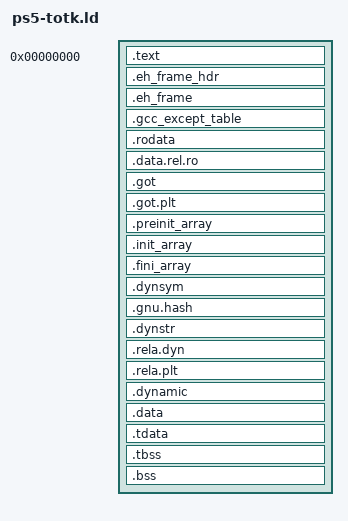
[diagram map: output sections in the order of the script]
/*
 * ps5/ps5-totk.ld
 *
 * PS5 PIE linker script for TOTK (PPSA99199).
 * Extends the PS5 kit's ps5-pie-unwind.ld by keeping TOTK's HOST_OVERRIDE
 * (`totk_ovr`) and HOST_OBSERVER (`totk_obs`) tables inside `: relro` with
 * explicit __start_totk_* / __stop_totk_* markers so --gc-sections never
 * strips them and PIE relocations fix up every entry's string & function ptr.
 */

OUTPUT_FORMAT("elf64-x86-64")
OUTPUT_ARCH(i386:x86-64)

PHDRS {
    text PT_LOAD FLAGS (0x5);
    ro PT_LOAD FLAGS (0x4);
    relro PT_LOAD FLAGS (0x6);
    data PT_LOAD FLAGS (0x6);
    dynamic PT_DYNAMIC FLAGS (0x6);
}

SECTIONS {
    .text 0 : ALIGN(CONSTANT(MAXPAGESIZE)) {
        QUAD(0xcccccccccccccccc)
        QUAD(0xcccccccccccccccc)
        PROVIDE_HIDDEN(__totk_lifted_start = .);
        *main/main_*.o(.text .text.*)
        *subsdk*/subsdk*.o(.text .text.*)
        *sdk/sdk_*.o(.text .text.*)
        PROVIDE_HIDDEN(__totk_lifted_end = .);
        *(.text .text.*)
        *(.plt .plt.*)
    } : text

    .eh_frame_hdr : ALIGN(CONSTANT(MAXPAGESIZE)) {
        KEEP(*(.eh_frame_hdr))
    } : ro
    .eh_frame : { KEEP(*(.eh_frame)) } : ro
    .gcc_except_table : { *(.gcc_except_table .gcc_except_table.*) } : ro
    .rodata : { *(.rodata .rodata.*) } : ro

    . = ALIGN(CONSTANT(MAXPAGESIZE));
    .data.rel.ro : {
        *(.data.rel.ro .data.rel.ro.*)
        . = ALIGN(8);
        PROVIDE_HIDDEN(__start_totk_ovr = .);
        KEEP(*(totk_ovr))
        PROVIDE_HIDDEN(__stop_totk_ovr = .);
        . = ALIGN(8);
        PROVIDE_HIDDEN(__start_totk_obs = .);
        KEEP(*(totk_obs))
        PROVIDE_HIDDEN(__stop_totk_obs = .);
    } : relro
    .got : { *(.got) } : relro
    .got.plt : { *(.got.plt) } : relro
    .preinit_array : {
        PROVIDE_HIDDEN(__preinit_array_start = .);
        KEEP(*(.preinit_array))
        PROVIDE_HIDDEN(__preinit_array_end = .);
    } : relro
    .init_array : {
        PROVIDE_HIDDEN(__init_array_start = .);
        KEEP(*(SORT_BY_INIT_PRIORITY(.init_array.*) SORT_BY_INIT_PRIORITY(.ctors.*)))
        KEEP(*(.init_array .ctors))
        PROVIDE_HIDDEN(__init_array_end = .);
    } : relro
    .fini_array : {
        PROVIDE_HIDDEN(__fini_array_start = .);
        KEEP(*(SORT_BY_INIT_PRIORITY(.fini_array.*) SORT_BY_INIT_PRIORITY(.dtors.*)))
        KEEP(*(.fini_array .dtors))
        PROVIDE_HIDDEN(__fini_array_end = .);
    } : relro

    .dynsym : { *(.dynsym) } : relro
    .gnu.hash : { *(.gnu.hash) } : relro
    .dynstr : { *(.dynstr) } : relro
    .rela.dyn : { *(.rela.dyn) } : relro
    .rela.plt : { *(.rela.plt) } : relro

    . = ALIGN(CONSTANT(MAXPAGESIZE));
    .dynamic : {
        *(.dynamic)
    } : data : dynamic
    .data : { *(.data .data.*) } : data
    .tdata : { *(.tdata .tdata.*) } : data
    .tbss : { *(.tbss .tbss.*) } : data
    .bss : {
        *(.bss .bss.*)
        *(COMMON)
    } : data
}

PROVIDE(__eh_frame_start = ADDR(.eh_frame));
PROVIDE(__eh_frame_end = ADDR(.eh_frame) + SIZEOF(.eh_frame));
PROVIDE(__eh_frame_hdr_start = ADDR(.eh_frame_hdr));
PROVIDE(__eh_frame_hdr_end = ADDR(.eh_frame_hdr) + SIZEOF(.eh_frame_hdr));
